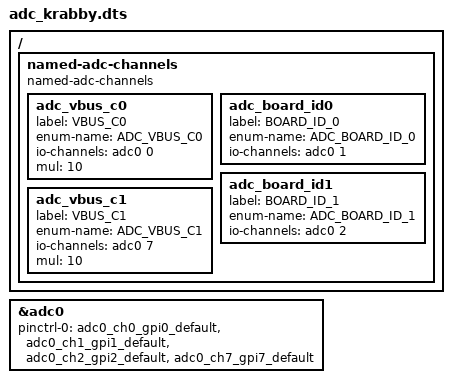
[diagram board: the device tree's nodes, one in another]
/* Copyright 2021 The Chromium OS Authors. All rights reserved.
 * Use of this source code is governed by a BSD-style license that can be
 * found in the LICENSE file.
 */

/ {
	named-adc-channels {
		compatible = "named-adc-channels";

		adc_vbus_c0 {
			label = "VBUS_C0";
			enum-name = "ADC_VBUS_C0";
			io-channels = <&adc0 0>;
			mul = <10>;
		};
		adc_board_id0 {
			label = "BOARD_ID_0";
			enum-name = "ADC_BOARD_ID_0";
			io-channels = <&adc0 1>;
		};
		adc_board_id1 {
			label = "BOARD_ID_1";
			enum-name = "ADC_BOARD_ID_1";
			io-channels = <&adc0 2>;
		};
		adc_vbus_c1 {
			label = "VBUS_C1";
			enum-name = "ADC_VBUS_C1";
			io-channels = <&adc0 7>;
			mul = <10>;
		};
	};
};

&adc0 {
	status = "okay";
	pinctrl-0 = <&adc0_ch0_gpi0_default
		     &adc0_ch1_gpi1_default
		     &adc0_ch2_gpi2_default
		     &adc0_ch7_gpi7_default>;
	pinctrl-names = "default";
};
